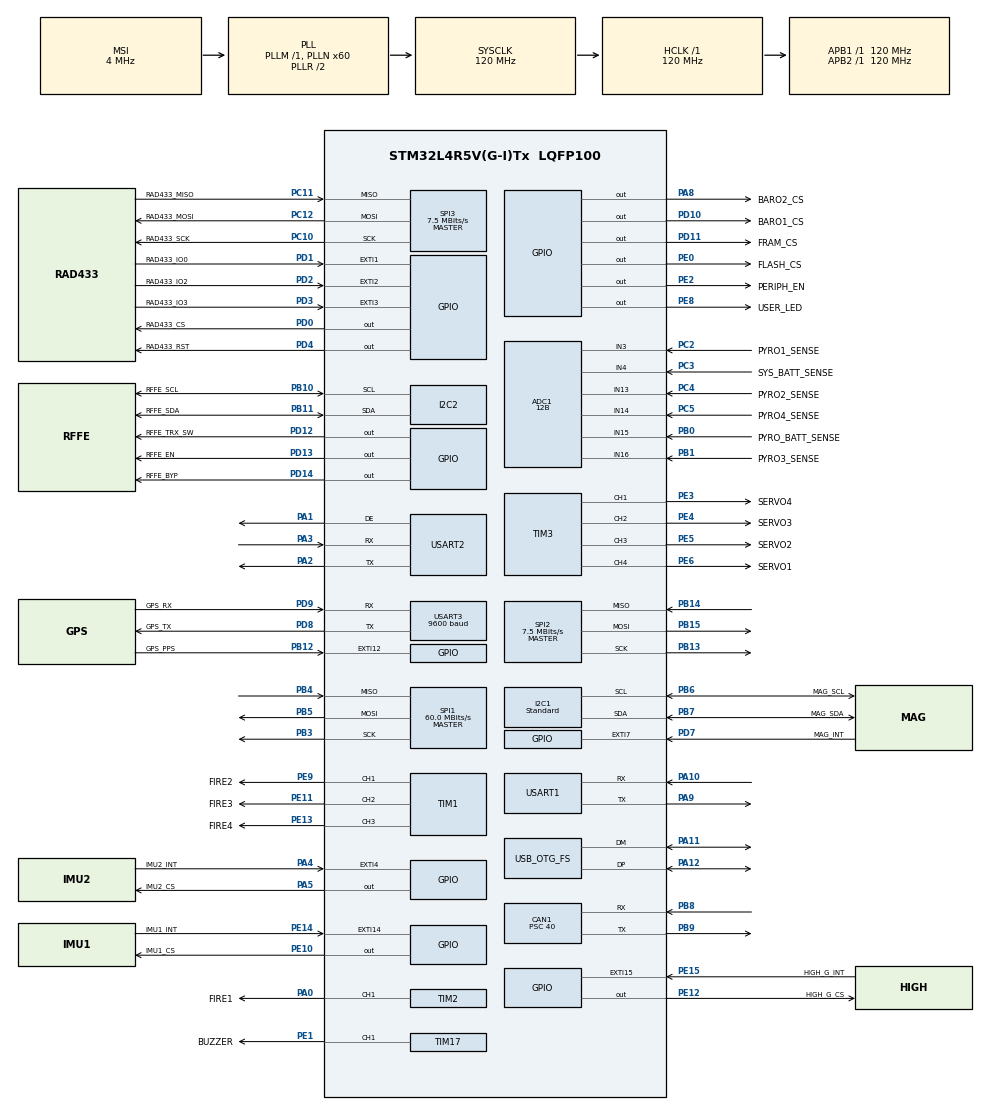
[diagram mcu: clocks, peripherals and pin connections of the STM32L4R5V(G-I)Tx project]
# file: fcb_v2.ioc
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ADC1.Channel-2\#ChannelRegularConversion=ADC_CHANNEL_3
ADC1.Channel-3\#ChannelRegularConversion=ADC_CHANNEL_13
ADC1.Channel-4\#ChannelRegularConversion=ADC_CHANNEL_16
ADC1.Channel-5\#ChannelRegularConversion=ADC_CHANNEL_14
ADC1.Channel-6\#ChannelRegularConversion=ADC_CHANNEL_4
ADC1.Channel-7\#ChannelRegularConversion=ADC_CHANNEL_15
ADC1.ClockPrescaler=ADC_CLOCK_ASYNC_DIV4
ADC1.ContinuousConvMode=DISABLE
ADC1.NbrOfConversion=6
ADC1.NbrOfConversionFlag=1
ADC1.OffsetNumber-2\#ChannelRegularConversion=ADC_OFFSET_NONE
ADC1.OffsetNumber-3\#ChannelRegularConversion=ADC_OFFSET_NONE
ADC1.OffsetNumber-4\#ChannelRegularConversion=ADC_OFFSET_NONE
ADC1.OffsetNumber-5\#ChannelRegularConversion=ADC_OFFSET_NONE
ADC1.OffsetNumber-6\#ChannelRegularConversion=ADC_OFFSET_NONE
ADC1.OffsetNumber-7\#ChannelRegularConversion=ADC_OFFSET_NONE
ADC1.Rank-2\#ChannelRegularConversion=1
ADC1.Rank-3\#ChannelRegularConversion=2
ADC1.Rank-4\#ChannelRegularConversion=3
ADC1.Rank-5\#ChannelRegularConversion=4
ADC1.Rank-6\#ChannelRegularConversion=5
ADC1.Rank-7\#ChannelRegularConversion=6
ADC1.Resolution=ADC_RESOLUTION_12B
ADC1.SamplingTime-2\#ChannelRegularConversion=ADC_SAMPLETIME_6CYCLES_5
ADC1.SamplingTime-3\#ChannelRegularConversion=ADC_SAMPLETIME_6CYCLES_5
ADC1.SamplingTime-4\#ChannelRegularConversion=ADC_SAMPLETIME_6CYCLES_5
ADC1.SamplingTime-5\#ChannelRegularConversion=ADC_SAMPLETIME_6CYCLES_5
ADC1.SamplingTime-6\#ChannelRegularConversion=ADC_SAMPLETIME_6CYCLES_5
ADC1.SamplingTime-7\#ChannelRegularConversion=ADC_SAMPLETIME_6CYCLES_5
ADC1.master=1
CAN1.BS1=CAN_BS1_1TQ
CAN1.BS2=CAN_BS2_1TQ
CAN1.CalculateBaudRate=999999
CAN1.CalculateTimeBit=1000
CAN1.CalculateTimeQuantum=333.33333333333337
CAN1.Prescaler=40
Dma.ADC1.2.Direction=DMA_PERIPH_TO_MEMORY
Dma.ADC1.2.EventEnable=DISABLE
Dma.ADC1.2.Instance=DMA1_Channel3
Dma.ADC1.2.MemDataAlignment=DMA_MDATAALIGN_WORD
Dma.ADC1.2.MemInc=DMA_MINC_ENABLE
Dma.ADC1.2.Mode=DMA_NORMAL
Dma.ADC1.2.PeriphDataAlignment=DMA_PDATAALIGN_WORD
Dma.ADC1.2.PeriphInc=DMA_PINC_DISABLE
Dma.ADC1.2.Polarity=HAL_DMAMUX_REQUEST_GEN_RISING
Dma.ADC1.2.Priority=DMA_PRIORITY_LOW
Dma.ADC1.2.RequestNumber=1
Dma.ADC1.2.SignalID=NONE
Dma.ADC1.2.SyncEnable=DISABLE
Dma.ADC1.2.SyncPolarity=HAL_DMAMUX_SYNC_NO_EVENT
Dma.ADC1.2.SyncRequestNumber=1
Dma.ADC1.2.SyncSignalID=NONE
Dma.Request0=USART3_RX
Dma.Request1=USART1_RX
Dma.Request2=ADC1
Dma.USART1_RX.1.Direction=DMA_PERIPH_TO_MEMORY
Dma.USART1_RX.1.EventEnable=DISABLE
Dma.USART1_RX.1.Instance=DMA1_Channel2
Dma.USART1_RX.1.MemDataAlignment=DMA_MDATAALIGN_BYTE
Dma.USART1_RX.1.MemInc=DMA_MINC_ENABLE
Dma.USART1_RX.1.Mode=DMA_NORMAL
Dma.USART1_RX.1.PeriphDataAlignment=DMA_PDATAALIGN_BYTE
Dma.USART1_RX.1.PeriphInc=DMA_PINC_DISABLE
Dma.USART1_RX.1.Polarity=HAL_DMAMUX_REQUEST_GEN_RISING
Dma.USART1_RX.1.Priority=DMA_PRIORITY_LOW
Dma.USART1_RX.1.RequestNumber=1
Dma.USART1_RX.1.SignalID=NONE
Dma.USART1_RX.1.SyncEnable=DISABLE
Dma.USART1_RX.1.SyncPolarity=HAL_DMAMUX_SYNC_NO_EVENT
Dma.USART1_RX.1.SyncRequestNumber=1
Dma.USART1_RX.1.SyncSignalID=NONE
Dma.USART3_RX.0.Direction=DMA_PERIPH_TO_MEMORY
Dma.USART3_RX.0.EventEnable=DISABLE
Dma.USART3_RX.0.Instance=DMA1_Channel1
Dma.USART3_RX.0.MemDataAlignment=DMA_MDATAALIGN_BYTE
Dma.USART3_RX.0.MemInc=DMA_MINC_ENABLE
Dma.USART3_RX.0.Mode=DMA_NORMAL
Dma.USART3_RX.0.PeriphDataAlignment=DMA_PDATAALIGN_BYTE
Dma.USART3_RX.0.PeriphInc=DMA_PINC_DISABLE
Dma.USART3_RX.0.Polarity=HAL_DMAMUX_REQUEST_GEN_RISING
Dma.USART3_RX.0.Priority=DMA_PRIORITY_LOW
Dma.USART3_RX.0.RequestNumber=1
Dma.USART3_RX.0.SignalID=NONE
Dma.USART3_RX.0.SyncEnable=DISABLE
Dma.USART3_RX.0.SyncPolarity=HAL_DMAMUX_SYNC_NO_EVENT
Dma.USART3_RX.0.SyncRequestNumber=1
Dma.USART3_RX.0.SyncSignalID=NONE
I2C1.I2C_Speed_Mode=I2C_Standard
I2C1.Timing=0x307075B1
I2C2.Timing=0x307075B1
IWDG.Prescaler=IWDG_PRESCALER_128
IWDG.Reload=1249
Mcu.Family=STM32L4
Mcu.Name=STM32L4R5V(G-I)Tx
Mcu.Package=LQFP100
NVIC.ADC1_IRQn=true\:0\:0\:false\:false\:true\:true\:true\:true
NVIC.DMA1_Channel1_IRQn=true\:0\:0\:false\:false\:true\:false\:true\:true
NVIC.DMA1_Channel2_IRQn=true\:0\:0\:false\:false\:true\:false\:true\:true
NVIC.DMA1_Channel3_IRQn=true\:0\:0\:false\:false\:true\:false\:true\:true
NVIC.OTG_FS_IRQn=true\:0\:0\:false\:false\:true\:true\:true\:true
NVIC.PriorityGroup=NVIC_PRIORITYGROUP_4
NVIC.USART1_IRQn=true\:0\:0\:false\:false\:true\:true\:true\:true
NVIC.USART3_IRQn=true\:0\:0\:false\:false\:true\:true\:true\:true
PA0.GPIO_Label=FIRE1
PA0.Signal=S_TIM2_CH1
PA1.Mode=Hardware Flow Control (RS485)
PA1.Signal=USART2_DE
PA10.Mode=Asynchronous
PA10.Signal=USART1_RX
PA11.Mode=Device_Only
PA11.Signal=USB_OTG_FS_DM
PA12.Mode=Device_Only
PA12.Signal=USB_OTG_FS_DP
PA13\ (JTMS/SWDIO).Mode=Serial_Wire
PA13\ (JTMS/SWDIO).Signal=SYS_JTMS-SWDIO
PA14\ (JTCK/SWCLK).Mode=Serial_Wire
PA14\ (JTCK/SWCLK).Signal=SYS_JTCK-SWCLK
PA2.Mode=Asynchronous
PA2.Signal=USART2_TX
PA3.Mode=Asynchronous
PA3.Signal=USART2_RX
PA4.GPIO_Label=IMU2_INT
PA4.Signal=GPXTI4
PA5.GPIO_Label=IMU2_CS
PA5.Signal=GPIO_Output
PA8.GPIO_Label=BARO2_CS
PA8.Signal=GPIO_Output
PA9.Mode=Asynchronous
PA9.Signal=USART1_TX
PB0.GPIO_Label=PYRO_BATT_SENSE
PB0.Signal=ADCx_IN15
PB1.GPIO_Label=PYRO3_SENSE
PB1.Signal=ADCx_IN16
PB10.GPIO_Label=RFFE_SCL
PB10.Mode=I2C
PB10.Signal=I2C2_SCL
PB11.GPIO_Label=RFFE_SDA
PB11.Mode=I2C
PB11.Signal=I2C2_SDA
PB12.GPIO_Label=GPS_PPS
PB12.Signal=GPXTI12
PB13.Mode=Full_Duplex_Master
PB13.Signal=SPI2_SCK
PB14.Mode=Full_Duplex_Master
PB14.Signal=SPI2_MISO
PB15.Mode=Full_Duplex_Master
PB15.Signal=SPI2_MOSI
PB3\ (JTDO/TRACESWO).Mode=Full_Duplex_Master
PB3\ (JTDO/TRACESWO).Signal=SPI1_SCK
PB4\ (NJTRST).Mode=Full_Duplex_Master
PB4\ (NJTRST).Signal=SPI1_MISO
PB5.Mode=Full_Duplex_Master
PB5.Signal=SPI1_MOSI
PB6.GPIO_Label=MAG_SCL
PB6.Mode=I2C
PB6.Signal=I2C1_SCL
PB7.GPIO_Label=MAG_SDA
PB7.Mode=I2C
PB7.Signal=I2C1_SDA
PB8.Mode=CAN_Activate
PB8.Signal=CAN1_RX
PB9.Mode=CAN_Activate
PB9.Signal=CAN1_TX
PC10.GPIO_Label=RAD433_SCK
PC10.Mode=Full_Duplex_Master
PC10.Signal=SPI3_SCK
PC11.GPIO_Label=RAD433_MISO
PC11.Mode=Full_Duplex_Master
PC11.Signal=SPI3_MISO
PC12.GPIO_Label=RAD433_MOSI
PC12.Mode=Full_Duplex_Master
PC12.Signal=SPI3_MOSI
PC14-OSC32_IN\ (PC14).Mode=LSE-External-Oscillator
PC14-OSC32_IN\ (PC14).Signal=RCC_OSC32_IN
PC15-OSC32_OUT\ (PC15).Mode=LSE-External-Oscillator
PC15-OSC32_OUT\ (PC15).Signal=RCC_OSC32_OUT
PC2.GPIO_Label=PYRO1_SENSE
PC2.Signal=ADCx_IN3
PC3.GPIO_Label=SYS_BATT_SENSE
PC3.Signal=ADCx_IN4
PC4.GPIO_Label=PYRO2_SENSE
PC4.Signal=ADCx_IN13
PC5.GPIO_Label=PYRO4_SENSE
PC5.Signal=ADCx_IN14
PD0.GPIO_Label=RAD433_CS
PD0.Signal=GPIO_Output
PD1.GPIO_Label=RAD433_IO0
PD1.Signal=GPXTI1
PD10.GPIO_Label=BARO1_CS
PD10.Signal=GPIO_Output
PD11.GPIO_Label=FRAM_CS
PD11.Signal=GPIO_Output
PD12.GPIO_Label=RFFE_TRX_SW
PD12.Signal=GPIO_Output
PD13.GPIO_Label=RFFE_EN
PD13.Signal=GPIO_Output
PD14.GPIO_Label=RFFE_BYP
PD14.Signal=GPIO_Output
PD2.GPIO_Label=RAD433_IO2
PD2.Signal=GPXTI2
PD3.GPIO_Label=RAD433_IO3
PD3.Signal=GPXTI3
PD4.GPIO_Label=RAD433_RST
PD4.Signal=GPIO_Output
PD7.GPIO_Label=MAG_INT
PD7.Signal=GPXTI7
PD8.GPIO_Label=GPS_TX
PD8.Mode=Asynchronous
PD8.Signal=USART3_TX
PD9.GPIO_Label=GPS_RX
PD9.Mode=Asynchronous
PD9.Signal=USART3_RX
PE0.GPIO_Label=FLASH_CS
PE0.Signal=GPIO_Output
PE1.GPIO_Label=BUZZER
PE1.Signal=S_TIM17_CH1
PE10.GPIO_Label=IMU1_CS
PE10.Signal=GPIO_Output
PE11.GPIO_Label=FIRE3
PE11.Signal=S_TIM1_CH2
PE12.GPIO_Label=HIGH_G_CS
PE12.Signal=GPIO_Output
PE13.GPIO_Label=FIRE4
PE13.Signal=S_TIM1_CH3
PE14.GPIO_Label=IMU1_INT
PE14.Signal=GPXTI14
PE15.GPIO_Label=HIGH_G_INT
PE15.Signal=GPXTI15
PE2.GPIO_Label=PERIPH_EN
PE2.Signal=GPIO_Output
PE3.GPIO_Label=SERVO4
PE3.Signal=S_TIM3_CH1
PE4.GPIO_Label=SERVO3
PE4.Signal=S_TIM3_CH2
PE5.GPIO_Label=SERVO2
PE5.Signal=S_TIM3_CH3
PE6.GPIO_Label=SERVO1
PE6.Signal=S_TIM3_CH4
PE8.GPIO_Label=USER_LED
PE8.Signal=GPIO_Output
PE9.GPIO_Label=FIRE2
PE9.Signal=S_TIM1_CH1
PH0-OSC_IN\ (PH0).Mode=HSE-External-Oscillator
PH0-OSC_IN\ (PH0).Signal=RCC_OSC_IN
PH1-OSC_OUT\ (PH1).Mode=HSE-External-Oscillator
PH1-OSC_OUT\ (PH1).Signal=RCC_OSC_OUT
ProjectManager.HeapSize=0x200
ProjectManager.StackSize=0x400
ProjectManager.TargetToolchain=STM32CubeIDE
RCC.ADCFreq_Value=12000000
RCC.AHBFreq_Value=120000000
RCC.APB1Freq_Value=120000000
RCC.APB1TimFreq_Value=120000000
RCC.APB2Freq_Value=120000000
RCC.APB2TimFreq_Value=120000000
RCC.CK48CLockSelection=RCC_USBCLKSOURCE_HSI48
RCC.CortexFreq_Value=120000000
RCC.HCLKFreq_Value=120000000
RCC.HSE_VALUE=8000000
RCC.HSI48_VALUE=48000000
RCC.HSI_VALUE=16000000
RCC.MSI_VALUE=4000000
RCC.PLLN=60
RCC.PLLSAI1N=24
RCC.PLLSAI1R=RCC_PLLR_DIV8
RCC.SYSCLKFreq_VALUE=120000000
RCC.SYSCLKSource=RCC_SYSCLKSOURCE_PLLCLK
RCC.USBFreq_Value=48000000
RCC.VCOOutputFreq_Value=240000000
SH.ADCx_IN13.0=ADC1_IN13,IN13-Single-Ended
SH.ADCx_IN14.0=ADC1_IN14,IN14-Single-Ended
SH.ADCx_IN15.0=ADC1_IN15,IN15-Single-Ended
SH.ADCx_IN16.0=ADC1_IN16,IN16-Single-Ended
SH.ADCx_IN3.0=ADC1_IN3,IN3-Single-Ended
SH.ADCx_IN4.0=ADC1_IN4,IN4-Single-Ended
SH.S_TIM17_CH1.0=TIM17_CH1,PWM Generation1 CH1
SH.S_TIM1_CH1.0=TIM1_CH1,PWM Generation1 CH1
SH.S_TIM1_CH2.0=TIM1_CH2,PWM Generation2 CH2
SH.S_TIM1_CH3.0=TIM1_CH3,PWM Generation3 CH3
SH.S_TIM2_CH1.0=TIM2_CH1,PWM Generation1 CH1
SH.S_TIM3_CH1.0=TIM3_CH1,PWM Generation1 CH1
SH.S_TIM3_CH2.0=TIM3_CH2,PWM Generation2 CH2
SH.S_TIM3_CH3.0=TIM3_CH3,PWM Generation3 CH3
SH.S_TIM3_CH4.0=TIM3_CH4,PWM Generation4 CH4
SPI1.BaudRatePrescaler=SPI_BAUDRATEPRESCALER_2
SPI1.CalculateBaudRate=60.0 MBits/s
SPI1.DataSize=SPI_DATASIZE_8BIT
SPI1.Direction=SPI_DIRECTION_2LINES
SPI1.Mode=SPI_MODE_MASTER
SPI1.VirtualType=VM_MASTER
SPI2.BaudRatePrescaler=SPI_BAUDRATEPRESCALER_16
SPI2.CalculateBaudRate=7.5 MBits/s
SPI2.DataSize=SPI_DATASIZE_8BIT
SPI2.Direction=SPI_DIRECTION_2LINES
SPI2.Mode=SPI_MODE_MASTER
SPI2.NSSPMode=SPI_NSS_PULSE_DISABLE
SPI2.VirtualType=VM_MASTER
SPI3.BaudRatePrescaler=SPI_BAUDRATEPRESCALER_16
SPI3.CalculateBaudRate=7.5 MBits/s
SPI3.DataSize=SPI_DATASIZE_8BIT
SPI3.Direction=SPI_DIRECTION_2LINES
SPI3.Mode=SPI_MODE_MASTER
SPI3.VirtualType=VM_MASTER
TIM1.Channel-PWM\ Generation1\ CH1=TIM_CHANNEL_1
TIM1.Channel-PWM\ Generation2\ CH2=TIM_CHANNEL_2
TIM1.Channel-PWM\ Generation3\ CH3=TIM_CHANNEL_3
TIM17.Channel=TIM_CHANNEL_1
TIM2.Channel-PWM\ Generation1\ CH1=TIM_CHANNEL_1
TIM3.Channel-PWM\ Generation1\ CH1=TIM_CHANNEL_1
TIM3.Channel-PWM\ Generation2\ CH2=TIM_CHANNEL_2
TIM3.Channel-PWM\ Generation3\ CH3=TIM_CHANNEL_3
TIM3.Channel-PWM\ Generation4\ CH4=TIM_CHANNEL_4
USART1.VirtualMode-Asynchronous=VM_ASYNC
USART2.VirtualMode-Asynchronous=VM_ASYNC
USART2.VirtualMode-Hardware\ Flow\ Control\ (RS485)=VM_ASYNC
USART3.BaudRate=9600
USART3.VirtualMode-Asynchronous=VM_ASYNC
USB_OTG_FS.VirtualMode=Device_Only
VP_IWDG_VS_IWDG.Mode=IWDG_Activate
VP_SYS_V_VREFBUF.Mode=ExternalMode
VP_TIM17_VS_ClockSourceINT.Mode=Enable_Timer
board=custom

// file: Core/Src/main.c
/* USER CODE BEGIN Header */
/**
  ******************************************************************************
  * @file           : main.c
  * @brief          : Main program body
  ******************************************************************************
  * @attention
  *
  * Copyright (c) 2023 STMicroelectronics.
  * All rights reserved.
  *
  * This software is licensed under terms that can be found in the LICENSE file
  * in the root directory of this software component.
  * If no LICENSE file comes with this software, it is provided AS-IS.
  *
  ******************************************************************************
  */
/* USER CODE END Header */
#include "main.h"
#include "adc.h"
#include "can.h"
#include "dma.h"
#include "i2c.h"
#include "iwdg.h"
#include "spi.h"
#include "tim.h"
#include "usart.h"
#include "usb_otg.h"
#include "gpio.h"

/* USER CODE BEGIN Includes */

#include "usbd_core.h"
#include "usbd_desc.h"
#include "usbd_composite.h"

/* USER CODE END Includes */

void SystemClock_Config(void);

/* USER CODE BEGIN 0 */

void main_cpp();

USBD_HandleTypeDef USBD_Device;

/* USER CODE END 0 */

int main(void)
{
  /* USER CODE BEGIN 1 */

	  /*
	  With code compiled outside Rowley, I'm seeing the USB ISR fire between USBD_Init() and USBD_RegisterClass().
	  Interrupts are enabled at reset, and ST's (mis)decision is to start enabling NVIC interrupts in USBD_Init().
	  By disabling interrupts here, and enabling later when everything is ready, we avoid this race condition.
	  */
	  __disable_irq();

  /* USER CODE END 1 */

  /* MCU Configuration--------------------------------------------------------*/

  /* Reset of all peripherals, Initializes the Flash interface and the Systick. */
  HAL_Init();

  /* Configure the system clock */
  SystemClock_Config();

  /* Initialize all configured peripherals */
  MX_GPIO_Init();
  MX_DMA_Init();
  MX_ADC1_Init();
  MX_CAN1_Init();
  MX_I2C2_Init();
  MX_SPI1_Init();
  MX_SPI2_Init();
  MX_SPI3_Init();
  MX_TIM1_Init();
  MX_TIM2_Init();
  MX_TIM3_Init();
  MX_USART2_UART_Init();
  MX_USART3_UART_Init();
  MX_I2C1_Init();
  MX_USART1_UART_Init();
  MX_TIM17_Init();
  MX_IWDG_Init();
  MX_USB_OTG_FS_PCD_Init();
  /* USER CODE BEGIN 2 */

  /* Initialize Device Library */
  USBD_Init(&USBD_Device, &USBD_Desc, 0);

  /* to work within ST's drivers, I've written a special USBD_Composite class that then invokes several classes */
  USBD_RegisterClass(&USBD_Device, &USBD_Composite);

  /* Start Device Process */
  USBD_Start(&USBD_Device);

  /* OK, only *now* it is OK for the USB interrupts to fire */
  __enable_irq();

  main_cpp();

  /* USER CODE END 2 */

  /* Infinite loop */
  while (1)
  {

  }
}

void SystemClock_Config(void)
{
  RCC_OscInitTypeDef RCC_OscInitStruct = {0};
  RCC_ClkInitTypeDef RCC_ClkInitStruct = {0};

  /** Configure the main internal regulator output voltage
  */
  if (HAL_PWREx_ControlVoltageScaling(PWR_REGULATOR_VOLTAGE_SCALE1_BOOST) != HAL_OK)
  {
    Error_Handler();
  }

  /** Initializes the RCC Oscillators according to the specified parameters
  * in the RCC_OscInitTypeDef structure.
  */
  RCC_OscInitStruct.OscillatorType = RCC_OSCILLATORTYPE_HSI48|RCC_OSCILLATORTYPE_LSI
                              |RCC_OSCILLATORTYPE_MSI;
  RCC_OscInitStruct.HSI48State = RCC_HSI48_ON;
  RCC_OscInitStruct.LSIState = RCC_LSI_ON;
  RCC_OscInitStruct.MSIState = RCC_MSI_ON;
  RCC_OscInitStruct.MSICalibrationValue = 0;
  RCC_OscInitStruct.MSIClockRange = RCC_MSIRANGE_6;
  RCC_OscInitStruct.PLL.PLLState = RCC_PLL_ON;
  RCC_OscInitStruct.PLL.PLLSource = RCC_PLLSOURCE_MSI;
  RCC_OscInitStruct.PLL.PLLM = 1;
  RCC_OscInitStruct.PLL.PLLN = 60;
  RCC_OscInitStruct.PLL.PLLP = RCC_PLLP_DIV2;
  RCC_OscInitStruct.PLL.PLLQ = RCC_PLLQ_DIV2;
  RCC_OscInitStruct.PLL.PLLR = RCC_PLLR_DIV2;
  if (HAL_RCC_OscConfig(&RCC_OscInitStruct) != HAL_OK)
  {
    Error_Handler();
  }

  /** Initializes the CPU, AHB and APB buses clocks
  */
  RCC_ClkInitStruct.ClockType = RCC_CLOCKTYPE_HCLK|RCC_CLOCKTYPE_SYSCLK
                              |RCC_CLOCKTYPE_PCLK1|RCC_CLOCKTYPE_PCLK2;
  RCC_ClkInitStruct.SYSCLKSource = RCC_SYSCLKSOURCE_PLLCLK;
  RCC_ClkInitStruct.AHBCLKDivider = RCC_SYSCLK_DIV1;
  RCC_ClkInitStruct.APB1CLKDivider = RCC_HCLK_DIV1;
  RCC_ClkInitStruct.APB2CLKDivider = RCC_HCLK_DIV1;

  if (HAL_RCC_ClockConfig(&RCC_ClkInitStruct, FLASH_LATENCY_5) != HAL_OK)
  {
    Error_Handler();
  }
}

void Error_Handler(void)
{
  __disable_irq();
  while (1)
  {
  }
}
